AUTOSAR XML (schema 4.0)
package /ExampleEcuProject/Interfaces
  11 x sender receiver interface:
    SpeedSignal_I
      data VehicleSpeed: type=uint16
    PedalPosition_I
      data PedalPosition: type=uint8
    TemperatureSignal_I
      data TemperatureValue: type=uint16
    TorqueRequest_I
      data RequestedTorque: type=uint16
    PressureSignal_I
      data BoostPressure: type=uint16
    DiagnosticStatus_I
      data FaultState: type=uint8
    ActuatorCommand_I
      data ThrottleDuty: type=uint8
    PositionFeedback_I
      data ActuatorPosition: type=uint8
    HealthStatus_I
      data HealthState: type=uint8
    EventSignal_I
      data EventCode: type=uint8
    FaultCounter_I
      data FaultCounter: type=uint16
  6 x client server interface:
    CalibrationService_I
      operation ReadCalibration
    SensorSyncService_I
      operation SynchronizeSensor
    FaultMemoryService_I
      operation StoreFault
    DiagnosticsControl_I
      operation RunSelfTest
    HealthMonitorService_I
      operation QueryHealth
    ActuationControlService_I
      operation EnableActuation
package /ExampleEcuProject/DataTypes
  app type uint8
  app type uint16
  app type uint32
package /ExampleEcuProject/ImplementationDataTypes
  impl type DiagAdminRequestContext
package /ExampleEcuProject/Modes
  mode declaration group PowerModeGroup: initial-mode=POWER_ON
    mode POWER_ON
    mode LOW_POWER
    mode SLEEP
package /ExampleEcuProject/Components
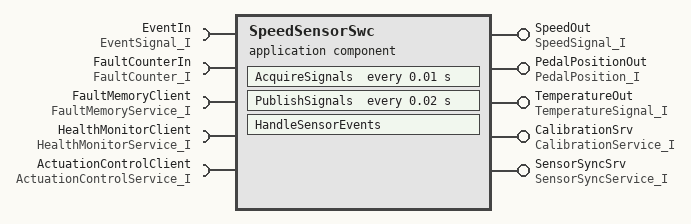
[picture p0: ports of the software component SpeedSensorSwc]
  application sw component type SpeedSensorSwc
    5 x provide port:
      SpeedOut: provided-interface=SpeedSignal_I
      PedalPositionOut: provided-interface=PedalPosition_I
      TemperatureOut: provided-interface=TemperatureSignal_I
      CalibrationSrv: provided-interface=CalibrationService_I
      SensorSyncSrv: provided-interface=SensorSyncService_I
    5 x require port:
      EventIn: required-interface=EventSignal_I
      FaultCounterIn: required-interface=FaultCounter_I
      FaultMemoryClient: required-interface=FaultMemoryService_I
      HealthMonitorClient: required-interface=HealthMonitorService_I
      ActuationControlClient: required-interface=ActuationControlService_I
    behavior SpeedSensorBehavior
      runnable AcquireSignals: symbol=SpeedSensor_AcquireSignals, minimum-start-interval=0.01
        parameter access ReadSpeedScaleCalibration
        parameter access ReadTemperatureOffsetCalibration
      runnable PublishSignals: symbol=SpeedSensor_PublishSignals, minimum-start-interval=0.01
        read-local-variables:
          access ReadRawSpeedIrv
          access ReadFilteredTemperatureIrv
        data-send-points:
          access SendVehicleSpeed: scope=communicationInterEcu
          access SendPedalPosition: scope=communicationInterEcu
          access SendTemperature: scope=communicationInterEcu
      runnable HandleSensorEvents: symbol=SpeedSensor_HandleSensorEvents, minimum-start-interval=0.05, can-be-invoked-concurrently=true
        data-receive-point-by-arguments:
          access ReceiveEventCode: scope=communicationIntraPartition
          access ReceiveFaultCounter: scope=communicationIntraPartition
        sync call StoreSensorFault: operation=FaultMemoryClient.StoreFault
      timing event AcquireSignalsEvent: start-on-event=AcquireSignals, period=0.01
      timing event PublishSignalsEvent: start-on-event=PublishSignals, period=0.02
      data received event HandleSensorEventTrigger: start-on-event=HandleSensorEvents, data=EventIn.EventCode
      parameter data prototype SpeedScale_C: type=uint16, init-value=1000
      parameter data prototype TemperatureOffset_C: type=uint16, init-value=25
      inter-runnable-variables:
        data RawSpeed_Irv: type=uint16
        data FilteredTemperature_Irv: type=uint16
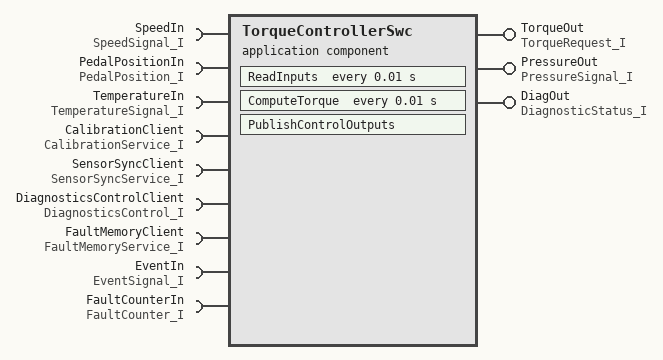
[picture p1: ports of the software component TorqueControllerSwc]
  application sw component type TorqueControllerSwc
    7 x require port:
      SpeedIn: required-interface=SpeedSignal_I
      PedalPositionIn: required-interface=PedalPosition_I
      TemperatureIn: required-interface=TemperatureSignal_I
      CalibrationClient: required-interface=CalibrationService_I
      SensorSyncClient: required-interface=SensorSyncService_I
      DiagnosticsControlClient: required-interface=DiagnosticsControl_I
      FaultMemoryClient: required-interface=FaultMemoryService_I
    provide port TorqueOut: provided-interface=TorqueRequest_I
    provide port PressureOut: provided-interface=PressureSignal_I
    provide port DiagOut: provided-interface=DiagnosticStatus_I
    require port EventIn: required-interface=EventSignal_I
    require port FaultCounterIn: required-interface=FaultCounter_I
    behavior TorqueControllerBehavior
      runnable ReadInputs: symbol=TorqueController_ReadInputs, minimum-start-interval=0.01
        data-read-access:
          access ReadVehicleSpeed: scope=communicationIntraPartition
          access ReadPedalPosition: scope=communicationIntraPartition
          access ReadTemperature: scope=communicationIntraPartition
        sync call ReadCalibration: operation=CalibrationClient.ReadCalibration
      runnable ComputeTorque: symbol=TorqueController_ComputeTorque, minimum-start-interval=0.01, can-be-invoked-concurrently=true
        parameter access ReadTorqueGain
        parameter access ReadPressureLimit
        written-local-variables:
          access WriteRequestedTorqueIrv
      runnable PublishControlOutputs: symbol=TorqueController_PublishControlOutputs, minimum-start-interval=0.02
        read-local-variables:
          access ReadRequestedTorqueIrv
        data-receive-point-by-arguments:
          access ReceiveFaultCounter: scope=communicationIntraPartition
        data-send-points:
          access SendTorqueRequest: scope=communicationInterEcu
          access SendPressureValue: scope=communicationInterEcu
          access SendDiagnosticStatus: scope=communicationInterEcu
      timing event ReadInputsEvent: start-on-event=ReadInputs, period=0.01
      timing event ComputeTorqueEvent: start-on-event=ComputeTorque, period=0.01
      data received event PublishControlOutputsEvent: start-on-event=PublishControlOutputs, data=FaultCounterIn.FaultCounter
      parameter data prototype TorqueGain_C: type=uint16, init-value=320
      parameter data prototype PressureLimit_C: type=uint16, init-value=1800
      inter-runnable-variables:
        data RequestedTorque_Irv: type=uint16
        data DiagnosticState_Irv: type=uint8
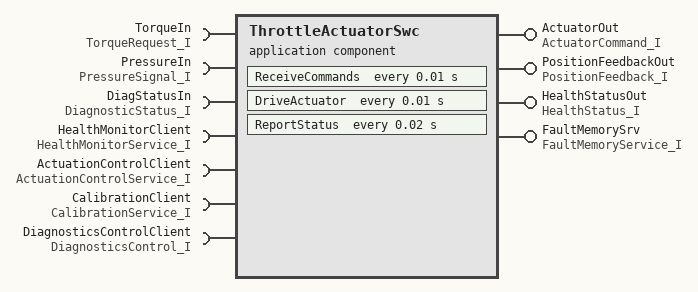
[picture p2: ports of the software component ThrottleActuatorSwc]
  application sw component type ThrottleActuatorSwc
    7 x require port:
      TorqueIn: required-interface=TorqueRequest_I
      PressureIn: required-interface=PressureSignal_I
      DiagStatusIn: required-interface=DiagnosticStatus_I
      HealthMonitorClient: required-interface=HealthMonitorService_I
      ActuationControlClient: required-interface=ActuationControlService_I
      CalibrationClient: required-interface=CalibrationService_I
      DiagnosticsControlClient: required-interface=DiagnosticsControl_I
    4 x provide port:
      ActuatorOut: provided-interface=ActuatorCommand_I
      PositionFeedbackOut: provided-interface=PositionFeedback_I
      HealthStatusOut: provided-interface=HealthStatus_I
      FaultMemorySrv: provided-interface=FaultMemoryService_I
    behavior ThrottleActuatorBehavior
      runnable ReceiveCommands: symbol=ThrottleActuator_ReceiveCommands, minimum-start-interval=0.01
        data-read-access:
          access ReadTorqueRequest: scope=communicationInterEcu
          access ReadPressureValue: scope=communicationInterEcu
          access ReadDiagStatus: scope=communicationInterEcu
        written-local-variables:
          access WriteDesiredDutyIrv
      runnable DriveActuator: symbol=ThrottleActuator_DriveActuator, minimum-start-interval=0.01
        parameter access ReadActuatorSlewRate
        parameter access ReadHomePosition
        read-local-variables:
          access ReadDesiredDutyIrv
        sync call RequestActuationEnable: operation=ActuationControlClient.EnableActuation
      runnable ReportStatus: symbol=ThrottleActuator_ReportStatus, minimum-start-interval=0.02, can-be-invoked-concurrently=true
        read-local-variables:
          access ReadMeasuredPositionIrv
        data-send-points:
          access SendActuatorCommand: scope=communicationInterEcu
          access SendPositionFeedback: scope=communicationInterEcu
          access SendHealthStatus: scope=communicationInterEcu
        sync call QueryHealthMonitor: operation=HealthMonitorClient.QueryHealth
      timing event ReceiveCommandsEvent: start-on-event=ReceiveCommands, period=0.01
      timing event DriveActuatorEvent: start-on-event=DriveActuator, period=0.01
      timing event ReportStatusEvent: start-on-event=ReportStatus, period=0.02
      parameter data prototype ActuatorSlewRate_C: type=uint16, init-value=75
      parameter data prototype HomePosition_C: type=uint8, init-value=10
      inter-runnable-variables:
        data DesiredDuty_Irv: type=uint8
        data MeasuredPosition_Irv: type=uint8
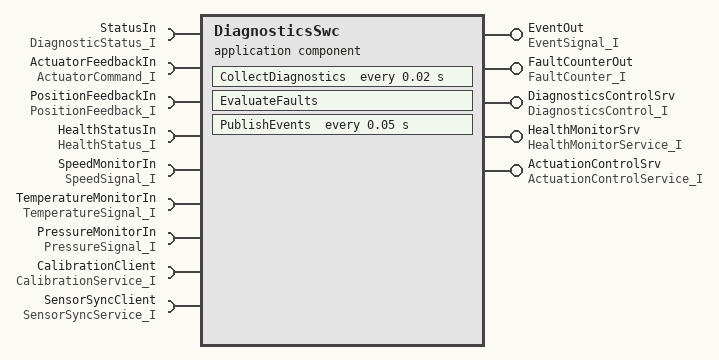
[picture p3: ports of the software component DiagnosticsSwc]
  application sw component type DiagnosticsSwc
    7 x require port:
      StatusIn: required-interface=DiagnosticStatus_I
      ActuatorFeedbackIn: required-interface=ActuatorCommand_I
      PositionFeedbackIn: required-interface=PositionFeedback_I
      HealthStatusIn: required-interface=HealthStatus_I
      SpeedMonitorIn: required-interface=SpeedSignal_I
      TemperatureMonitorIn: required-interface=TemperatureSignal_I
      PressureMonitorIn: required-interface=PressureSignal_I
    5 x provide port:
      EventOut: provided-interface=EventSignal_I
      FaultCounterOut: provided-interface=FaultCounter_I
      DiagnosticsControlSrv: provided-interface=DiagnosticsControl_I
      HealthMonitorSrv: provided-interface=HealthMonitorService_I
      ActuationControlSrv: provided-interface=ActuationControlService_I
    require port CalibrationClient: required-interface=CalibrationService_I
    require port SensorSyncClient: required-interface=SensorSyncService_I
    behavior DiagnosticsBehavior
      runnable CollectDiagnostics: symbol=Diagnostics_CollectDiagnostics, minimum-start-interval=0.02
        data-read-access:
          access ReadStatusInput: scope=communicationInterEcu
          access ReadActuatorFeedback: scope=communicationInterEcu
          access ReadPositionFeedback: scope=communicationInterEcu
      runnable EvaluateFaults: symbol=Diagnostics_EvaluateFaults, minimum-start-interval=0.05, can-be-invoked-concurrently=true
        parameter access ReadFaultDebounce
        parameter access ReadEventThreshold
        data-receive-point-by-arguments:
          access ReceiveDiagnosticStatus: scope=communicationInterEcu
        written-local-variables:
          access WriteFaultCounterIrv
          access WriteLatestEventCodeIrv
      runnable PublishEvents: symbol=Diagnostics_PublishEvents, minimum-start-interval=0.05
        read-local-variables:
          access ReadFaultCounterIrv
          access ReadLatestEventCodeIrv
        data-send-points:
          access SendEventCode: scope=communicationInterEcu
          access SendFaultCounter: scope=communicationInterEcu
      timing event CollectDiagnosticsEvent: start-on-event=CollectDiagnostics, period=0.02
      data received event EvaluateFaultsEvent: start-on-event=EvaluateFaults, data=StatusIn.FaultState
      timing event PublishEventsTrigger: start-on-event=PublishEvents, period=0.05
      parameter data prototype FaultDebounce_C: type=uint16, init-value=5
      parameter data prototype EventThreshold_C: type=uint8, init-value=3
      inter-runnable-variables:
        data FaultCounter_Irv: type=uint16
        data LatestEventCode_Irv: type=uint8
  composition sw component type PowertrainComposition
    4 x component:
      SpeedSensorInst: type=SpeedSensorSwc
      TorqueControllerInst: type=TorqueControllerSwc
      ThrottleActuatorInst: type=ThrottleActuatorSwc
      DiagnosticsInst: type=DiagnosticsSwc
    connect SpeedSensorInst.SpeedOut -> TorqueControllerInst.SpeedIn
    connect SpeedSensorInst.SpeedOut -> DiagnosticsInst.SpeedMonitorIn
    connect SpeedSensorInst.PedalPositionOut -> TorqueControllerInst.PedalPositionIn
    connect SpeedSensorInst.TemperatureOut -> TorqueControllerInst.TemperatureIn
    connect SpeedSensorInst.TemperatureOut -> DiagnosticsInst.TemperatureMonitorIn
    connect TorqueControllerInst.TorqueOut -> ThrottleActuatorInst.TorqueIn
    connect TorqueControllerInst.PressureOut -> ThrottleActuatorInst.PressureIn
    connect TorqueControllerInst.PressureOut -> DiagnosticsInst.PressureMonitorIn
    connect TorqueControllerInst.DiagOut -> DiagnosticsInst.StatusIn
    connect TorqueControllerInst.DiagOut -> ThrottleActuatorInst.DiagStatusIn
    connect ThrottleActuatorInst.ActuatorOut -> DiagnosticsInst.ActuatorFeedbackIn
    connect ThrottleActuatorInst.PositionFeedbackOut -> DiagnosticsInst.PositionFeedbackIn
    connect ThrottleActuatorInst.HealthStatusOut -> DiagnosticsInst.HealthStatusIn
    connect SpeedSensorInst.CalibrationSrv -> TorqueControllerInst.CalibrationClient
    connect SpeedSensorInst.CalibrationSrv -> ThrottleActuatorInst.CalibrationClient
    connect SpeedSensorInst.CalibrationSrv -> DiagnosticsInst.CalibrationClient
    connect SpeedSensorInst.SensorSyncSrv -> TorqueControllerInst.SensorSyncClient
    connect SpeedSensorInst.SensorSyncSrv -> DiagnosticsInst.SensorSyncClient
    connect ThrottleActuatorInst.FaultMemorySrv -> SpeedSensorInst.FaultMemoryClient
    connect ThrottleActuatorInst.FaultMemorySrv -> TorqueControllerInst.FaultMemoryClient
    connect DiagnosticsInst.DiagnosticsControlSrv -> TorqueControllerInst.DiagnosticsControlClient
    connect DiagnosticsInst.DiagnosticsControlSrv -> ThrottleActuatorInst.DiagnosticsControlClient
    connect DiagnosticsInst.HealthMonitorSrv -> ThrottleActuatorInst.HealthMonitorClient
    connect DiagnosticsInst.HealthMonitorSrv -> SpeedSensorInst.HealthMonitorClient
    connect DiagnosticsInst.ActuationControlSrv -> ThrottleActuatorInst.ActuationControlClient
    connect DiagnosticsInst.ActuationControlSrv -> SpeedSensorInst.ActuationControlClient
    connect DiagnosticsInst.EventOut -> SpeedSensorInst.EventIn
    connect DiagnosticsInst.EventOut -> TorqueControllerInst.EventIn
    connect DiagnosticsInst.FaultCounterOut -> SpeedSensorInst.FaultCounterIn
    connect DiagnosticsInst.FaultCounterOut -> TorqueControllerInst.FaultCounterIn
package /ExampleEcuProject/StandardsCoverage/Interfaces
  4 x sender receiver interface:
    RawCurrent_I
      data CurrentMilliAmp: type=uint16
    PhysicalSpeed_I
      data VehicleSpeedKph: type=uint16
    ActuatorEnable_I
      data EnableState: type=uint8
    WakeupStatus_I
      data WakeupReason: type=uint8
  client server interface DiagAdmin_I
    operation RequestSession: possible-error=DiagDenied_E
      arg RequestedSession: type=uint8
    error DiagDenied_E: error-code=7
  parameter interface SharedCalibration_I
    parameter data prototype SpeedGain: type=uint16
    parameter data prototype WakeupThreshold: type=uint16
  nv data interface SharedNvData_I
    nv-datas:
      data StoredWakeupCounter: type=uint16
  mode switch interface PowerMode_I
    mode declaration group prototype PowerMode: type=PowerModeGroup
  trigger interface WakeupTrigger_I
    trigger FastWakeup
    trigger SleepTransition
package /ExampleEcuProject/StandardsCoverage/Hardware
  hw type WheelSpeedSensorHw
  hw type MainIoExpanderHw
  hw type WakeupControllerHw
package /ExampleEcuProject/StandardsCoverage/Components
  parameter sw component type SharedCalibrationSwc
    provide port CalibrationOut: provided-interface=SharedCalibration_I
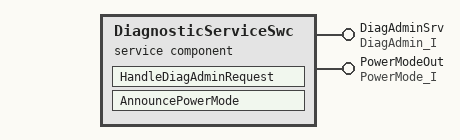
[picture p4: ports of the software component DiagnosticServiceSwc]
  service sw component type DiagnosticServiceSwc
    provide port DiagAdminSrv: provided-interface=DiagAdmin_I
    provide port PowerModeOut: provided-interface=PowerMode_I
    behavior DiagnosticServiceBehavior
      runnable HandleDiagAdminRequest: symbol=DiagAdminSrv_HandleRequest
      runnable AnnouncePowerMode: symbol=DiagAdminSrv_AnnouncePowerMode, minimum-start-interval=0.01
      operation invoked event HandleDiagAdminRequestEvent: start-on-event=HandleDiagAdminRequest, operation=DiagAdminSrv.RequestSession
      background event AnnouncePowerModeEvent: start-on-event=AnnouncePowerMode
      port-api-options:
        {port=DiagnosticServiceSwc/DiagAdminSrv, enable-take-address=true, indirect-api=true, error-handling=transformerErrorHandling, transformer-status-forwarding=transformerStatusForwarding, supported-features=communication-buffer-locking=support-buffer-locking=supportsBufferLocking, port-defined-argument-value{value-type=DiagAdminRequestContext, value=DiagAdmin}}
        port=DiagnosticServiceSwc/PowerModeOut, indirect-api=false
  service proxy sw component type DiagnosticProxySwc
    require port DiagAdminClient: required-interface=DiagAdmin_I
  nv block sw component type WakeupNvBlockSwc
    provide/require port NvMirrorPr: provided-required-interface=SharedNvData_I
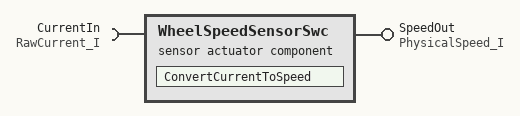
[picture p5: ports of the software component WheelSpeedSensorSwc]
  sensor actuator sw component type WheelSpeedSensorSwc: sensor-actuator=WheelSpeedSensorHw
    require port CurrentIn: required-interface=RawCurrent_I
    provide port SpeedOut: provided-interface=PhysicalSpeed_I
    behavior WheelSpeedSensorBehavior
      runnable ConvertCurrentToSpeed
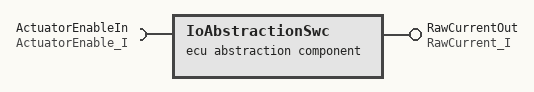
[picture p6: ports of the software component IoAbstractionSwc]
  ecu abstraction sw component type IoAbstractionSwc: hardware-element=MainIoExpanderHw
    swc bsw mapping IoAbstractionToBsw
    provide port RawCurrentOut: provided-interface=RawCurrent_I
    require port ActuatorEnableIn: required-interface=ActuatorEnable_I
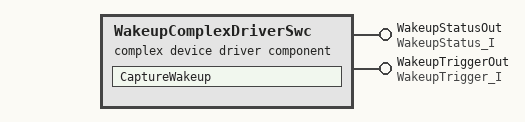
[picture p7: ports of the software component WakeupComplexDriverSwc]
  complex device driver sw component type WakeupComplexDriverSwc: hardware-element=WakeupControllerHw
    swc bsw mapping WakeupDriverToBsw
    provide port WakeupStatusOut: provided-interface=WakeupStatus_I
    provide port WakeupTriggerOut: provided-interface=WakeupTrigger_I
    provide/require port WakeupMirrorPr: provided-required-interface=SharedNvData_I
    behavior WakeupDriverBehavior
      runnable CaptureWakeup
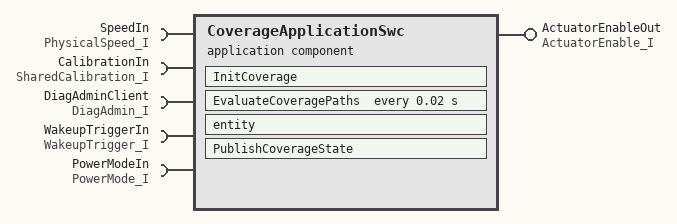
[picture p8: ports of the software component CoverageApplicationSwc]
  application sw component type CoverageApplicationSwc
    5 x require port:
      SpeedIn: required-interface=PhysicalSpeed_I
      CalibrationIn: required-interface=SharedCalibration_I
      DiagAdminClient: required-interface=DiagAdmin_I
      WakeupTriggerIn: required-interface=WakeupTrigger_I
      PowerModeIn: required-interface=PowerMode_I
    provide port ActuatorEnableOut: provided-interface=ActuatorEnable_I
    provide/require port WakeupDataPr: provided-required-interface=SharedNvData_I
    behavior CoverageApplicationBehavior: included-data-type-set{literal-prefix=COVERAGE_DT, data-type=[uint8, uint16]}, included-mode-declaration-group-set{prefix=COVERAGE_MODE, mode-declaration-group=PowerModeGroup}
      runnable InitCoverage: symbol=Coverage_InitCoverage
        parameter access ReadStartupCalibration
        data-read-access:
          access ReadWakeupMirrorOnInit: scope=communicationIntraPartition
        sync call RequestDefaultSession: operation=DiagAdminClient.RequestSession
        internal triggering point InitToEvaluateTrigger: sw-impl-policy=QUEUED
      runnable EvaluateCoveragePaths: symbol=Coverage_EvaluateCoveragePaths, minimum-start-interval=0.02, can-be-invoked-concurrently=true
        runnable entity argument ActivationReason: type=uint8
        data-read-access:
          access ReadSpeedImplicit: scope=communicationIntraPartition
          access ReadWakeupMirrorImplicit: scope=interPartitionIntraEcu
        data-receive-point-by-values:
          access ReceiveSpeedByValue: scope=communicationIntraPartition
        data-receive-point-by-arguments:
          access ReceiveWakeupCounterByArgument: scope=interPartitionIntraEcu
        data-write-access:
          access WriteActuatorEnableImplicit: scope=communicationInterEcu
        data-send-points:
          access SendActuatorEnableExplicit: scope=communicationInterEcu
        parameter access ReadCoverageCalibration
        async call RequestExtendedSession: timeout=0.05
        asynchronous server call result point AwaitExtendedSessionResult
        wait point WaitForDiagResult: timeout=0.05, trigger=SpeedInEvent
        external triggering point ForwardWakeupTrigger
        internal triggering point EvaluateToPublishTrigger
      runnable PublishCoverageState: symbol=Coverage_PublishCoverageState, minimum-start-interval=0.02
        read-local-variables:
          access ReadCoverageStateIrv
        written-local-variables:
          access WriteCoverageDebounceIrv
        data-send-points:
          access SendActuatorEnableState: scope=communicationInterEcu
      init event InitCoverageEvent: start-on-event=InitCoverage
      timing event EvaluateCoveragePathsEvent: start-on-event=EvaluateCoveragePaths, period=0.02
      data received event SpeedInEvent: start-on-event=EvaluateCoveragePaths, data=SpeedIn.VehicleSpeedKph
      data receive error event WakeupMirrorErrorEvent: start-on-event=PublishCoverageState, data=WakeupDataPr.StoredWakeupCounter
      external trigger occurred event WakeupTriggerEvent: start-on-event=EvaluateCoveragePaths
      internal trigger occurred event PublishCoverageStateEvent: start-on-event=PublishCoverageState, event-source=EvaluateToPublishTrigger
      exclusive area CoverageStateLock
      exclusive area DiagnosticSessionLock
      exclusive area nesting order CoverageLockOrder
      explicit-inter-runnable-variables:
        data CoverageStateIrv: type=uint8
      implicit-inter-runnable-variables:
        data CoverageDebounceIrv: type=uint16
      per instance memory CoverageScratchpad: type=uint8, type-definition=typedef uint8 CoverageScratchpadType;, init-value=0
      ar-typed-per-instance-memorys:
        data CoverageHistoryPim: type=uint16
      per-instance-parameters:
        parameter data prototype CoverageThresholdPerInstance: type=uint16
      parameter data prototype CoverageGain: type=uint16
      static-memorys:
        data CoverageDebugCounter: type=uint32
      constant-memorys:
        parameter data prototype CoverageConstTable: type=uint16
      port-api-options:
        port=CoverageApplicationSwc/SpeedIn, indirect-api=true
        port=WakeupDataPr, error-handling=transformerErrorHandling, transformer-status-forwarding=transformerStatusForwarding, supported-features=communication-buffer-locking=support-buffer-locking=supportsBufferLocking
      swc service dependency CoverageDiagDependency: diagnostic-relevance=isRelevant, assigned-ports=role-based-port-assignment={port-prototype=CoverageApplicationSwc/DiagAdminClient, role=DiagAdminClientRole}
        vendor specific service needs CoverageDiagVendorNeeds: category=COVERAGE_DIAGNOSTICS
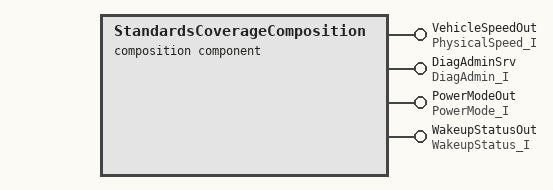
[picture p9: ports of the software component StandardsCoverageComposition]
  composition sw component type StandardsCoverageComposition
    4 x provide port:
      VehicleSpeedOut: provided-interface=PhysicalSpeed_I
      DiagAdminSrv: provided-interface=DiagAdmin_I
      PowerModeOut: provided-interface=PowerMode_I
      WakeupStatusOut: provided-interface=WakeupStatus_I
    8 x component:
      CalibrationInst: type=SharedCalibrationSwc
      ServiceInst: type=DiagnosticServiceSwc
      ProxyInst: type=DiagnosticProxySwc
      NvBlockInst: type=WakeupNvBlockSwc
      SensorInst: type=WheelSpeedSensorSwc
      EcuAbsInst: type=IoAbstractionSwc
      ComplexDriverInst: type=WakeupComplexDriverSwc
      ApplicationInst: type=CoverageApplicationSwc
    connect EcuAbsInst.RawCurrentOut -> SensorInst.CurrentIn
    connect SensorInst.SpeedOut -> ApplicationInst.SpeedIn
    connect CalibrationInst.CalibrationOut -> ApplicationInst.CalibrationIn
    connect ServiceInst.DiagAdminSrv -> ApplicationInst.DiagAdminClient
    connect ServiceInst.DiagAdminSrv -> ProxyInst.DiagAdminClient
    connect ApplicationInst.ActuatorEnableOut -> EcuAbsInst.ActuatorEnableIn
    delegate SensorInst.SpeedOut <-> outer port VehicleSpeedOut
    delegate ServiceInst.DiagAdminSrv <-> outer port StandardsCoverageComposition/DiagAdminSrv
    delegate ServiceInst.PowerModeOut <-> outer port StandardsCoverageComposition/PowerModeOut
    delegate ComplexDriverInst.WakeupStatusOut <-> outer port StandardsCoverageComposition/WakeupStatusOut
package /ExampleEcuProject/System
  system VehicleEcuSystem: fibex-element=PowertrainComposition
  ecu instance PowertrainEcu
